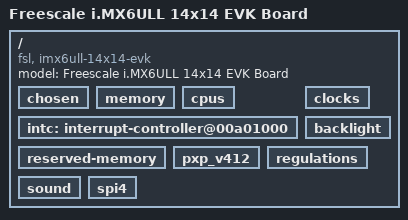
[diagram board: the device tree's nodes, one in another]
/dts-v1/;

#include .h
#include .dtsi
#include <skeleton.dtsi>

//从根节点开始
/ {
    //skeleton.dtsi文件， 相当于有了这些信息
    // compatible = "snps,arc";
	// #address-cells = <1>;
	// #size-cells = <1>;
	// chosen { };
	// aliases { };
    // memory {
	// 	device_type = "memory";
	// 	reg = <0x80000000 0x10000000>;	/* 256M */
	// };

    //一级子节点
    //该放什么由人去添加， 通常芯片厂会给出
    model = "Freescale i.MX6ULL 14x14 EVK Board";
    compatible = "fsl, imx6ull-14x14-evk", "fsl, imx6ull";

    chosen{

    };

    //内存相关的 子节点
    memory{

    };

    //
    cpus{

    };

    //中断控制器，对于芯片内部来说是个外设
    //所以肯定有首地址
    intc: interrupt-controller@00a01000{

    };

    //
    clocks{

    };

    //
    reserved-memory{

    };

    //背光相关的一级  子节点
    backlight{

    };

    pxp_v412{

    };

    regulations{

    };

    sound{

    };

    //子节点
    spi4{

    };
};

//从跟节点开始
